AUTOSAR XML (schema 4-2-2)
package /AUTOLIV/SoftwareComponents/SBC
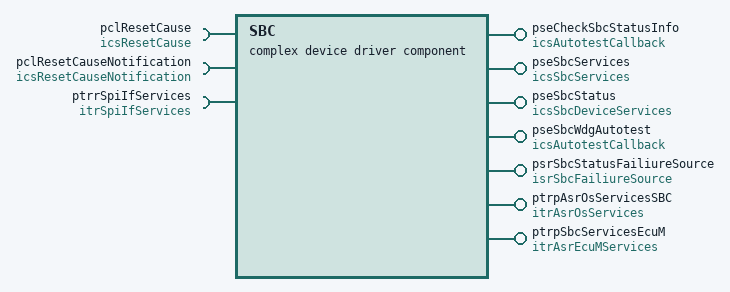
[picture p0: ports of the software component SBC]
  complex device driver sw component type SBC: category=MCAL_Communication_Abstraction
    require port pclResetCause: required-com-specs=[DetermineResetCause, GetResetCause], required-interface=icsResetCause  # Architecture Element ID - ARCH_SW_SBC_pclResetCause_SBC_Autotest_WdgTest # Description - The runnable shall provide the SBC reset reason to the application. # Data Flow ## Inputs ## Outputs # Linked Runnable - SBC_Autotest_WdgTest #Traceability
    require port pclResetCauseNotification: client-com-spec=NotifyResetCause, required-interface=icsResetCauseNotification  # Architecture Element ID - ARCH_SW_SBC_pclResetCauseNotification_SBC_Init # Description - The runnable shall store the SBC reset reason in the no init ram area. # Data Flow ## Inputs ## Outputs # Linked Runnable - SBC_Init #Traceability
    7 x provide port:
      pseCheckSbcStatusInfo: server-com-spec{operation=AutotestCallback, queue-length=1}, provided-interface=icsAutotestCallback  # Architecture Element ID - ARCH_SW_SBC_pseCheckSbcStatusInfo # Description - The autotest shall check the Status information section of a Spi response from the SBC chip - If one or more bits of status information are qualified within 100ms then the result of autotest shall be NOK # Data Flow ## Inputs ## Outputs - {Autotest Result} - Can be one of the following values: OK, NOK, NOT DECIDED # Linked Runnable - SBC_Autotest_CheckStatusInformation #Traceability DOM_eCS_TF_H_309 DOM_eCS_TF_H_310 DOM_eCS_TF_H_311 FUSA_DS_TLE9461_3ES_1034 FUSA_DS_TLE9461_3ES_1042 FUSA_DS_TLE9461_3ES_1046 FUSA_DS_TLE9461_3ES_1047 FUSA_DS_TLE9461_3ES_1058 FUSA_DS_TLE9461_3ES_1127
      pseSbcServices: provided-interface=icsSbcServices  # Architecture Element ID - ARCH_SW_SBC_pseSbcServicesLpm_SBC_sleepTriggerWatchdog # Description - The SBC_sleepTriggerWatchdog runnable shall be called by LPM module to trigger the watchdog during init and mainloop phase (LPM_sleepInit and LPM_sleepMainLoop) # Data Flow ## Inputs ## Outputs # Linked Runnable - SBC_sleepTriggerWatchdog #Traceability FUSA_DS_TLE9461_3ES_731 FUSA_DS_TLE9461_3ES_1000 FUSA_DS_TLE9461_3ES_1127 ------------------------------------------------------------------------------------ Architecture Element ID - ARCH_SW_SBC_pseSbcServicesLpm_SBC_SetToNormal # Description - The SBC_SetToNormal runnable shall be called to put the SBC in normal mode state (LPM_sleepRestore) # Data Flow ## Inputs ## Outputs # Linked Runnable - SBC_SetToNormal #Traceability FUSA_DS_TLE9461_3ES_1127 ------------------------------------------------------------------------------------ Architecture Element ID - ARCH_SW_SBC_pseSbcServicesLpm_SBC_SetToLowPower # Description - The SBC_SetToLowPower runnable shall be called to put the SBC in low power mode (LPM_sleepInit) # Data Flow ## Inputs ## Outputs # Linked Runnable - SBC_SetToLowPower #Traceability FUSA_DS_TLE9461_3ES_227 FUSA_DS_TLE9461_3ES_1127 ------------------------------------------------------------------------------------
        provided-com-specs:
          operation=SBC_sleepTriggerWatchdog, queue-length=1
          operation=SBC_SetToLowPower, queue-length=1
          operation=SBC_SetToNormal, queue-length=1
      pseSbcStatus: provided-interface=icsSbcDeviceServices  # Architecture Element ID - ARCH_SW_SBC_pseSbcStatus_SBC_GetSBCStatusInformation # Description - The runnable shall read the SBC status registers and report them via the {SBC Status Information} output parameter - The following flags should be reported: - Under voltage - CAN wake-up - Watchdog failure # Data Flow ## Inputs ## Outputs - {SBC Status Information} # Linked Runnable - SBC_GetSBCStatusInformation #Traceability FUSA_DS_TLE9461_3ES_1127 ------------------------------------------------------------------------------------ Architecture Element ID - ARCH_SW_SBC_pseSbcStatus_SBC_Shutdown # Description - The SBC_Shutdown runnable shall be called by the Autosar EcuM in deinitialization phase (EcuM_AL_SwitchOff) # Data Flow ## Inputs ## Outputs # Linked Runnable - SBC_Shutdown #Traceability FUSA_DS_TLE9461_3ES_1127 ------------------------------------------------------------------------------------ Architecture Element ID - ARCH_SW_SBC_pseSbcStatus_SBC_Reset # Description - The SBC_Reset runnable shall be called in order to make a reset (EcuM_AL_Reset and MIC_MachineExceptionInterrupt) # Data Flow ## Inputs ## Outputs # Linked Runnable - SBC_Reset #Traceability FUSA_DS_TLE9461_3ES_941 FUSA_DS_TLE9461_3ES_1127 ------------------------------------------------------------------------------------
        provided-com-specs:
          operation=SBC_Reset, queue-length=1
          operation=SBC_Shutdown, queue-length=1
          operation=GetSbcStatus, queue-length=1
      pseSbcWdgAutotest: server-com-spec{operation=AutotestCallback, queue-length=1}, provided-interface=icsAutotestCallback  # Architecture Element ID - ARCH_SW_SBC_pseSbcWdgAutotest # Description - The autotest shall check the Wdg from the SBC chip - The watchdog is enabled and never triggered, a reset is expected # Data Flow ## Inputs ## Outputs - {Autotest Result} - Can be one of the following values: OK, NOK # Linked Runnable - SBC_Autotest_WdgTest #Traceability FUSA_SM_S32K1XXSM_539 FUSA_SM_S32K1XXSM_541 FUSA_SM_S32K1XXSM_263 FUSA_SM_S32K1XXSM_291 DOM_eCS_TF_H_292 DOM_eCS_TF_H_293 FUSA_DS_TLE9461_3ES_1127
      psrSbcStatusFailiureSource: nonqueued-sender-com-spec{data-element=u32SbcReg1Status, uses-end-to-end-protection=0, init-value=0}, provided-interface=isrSbcFailiureSource  # Architecture Element ID - ARCH_SW_SBC_psrSbcStatusFailiureSource_SBC_Init # Description - The runnable shall read the content of the SBC status registers that were previously read from the SPI bus - The runnable shall write the content of the SBC Status Registers on the {SBC Status Register} output parameter. # Data Flow ## Inputs ## Outputs - {SBC Status Register} # Linked Runnable - SBC_Init #Traceability ------------------------------------------------------------------- Architecture Element ID - ARCH_SW_SBC_psrSbcStatusFailiureSource_SBC_runMainFunction # Description - The runnable shall read the content of the SBC status registers that were previously read from the SPI bus - The runnable shall write the content of the SBC Status Registers on the {SBC Status Register} output parameter. # Data Flow ## Inputs - None ## Outputs - {SBC Status Register} # Linked Runnable - SBC_runMainFunction #Traceability
      ptrpAsrOsServicesSBC: provided-interface=itrAsrOsServices  # Architecture Element ID - ARCH_SW_SBC_ptrpAsrOsServices # Description - The runnable shall be called periodically at 10ms in order to trigger the watchdog - The watchdog should be trigger in windowed mode each 40ms # Data Flow ## Inputs ## Outputs # Linked Runnable - SBC_runMainFunction #Traceability FUSA_DS_TLE9461_3ES_970 FUSA_DS_TLE9461_3ES_992 FUSA_DS_TLE9461_3ES_993 FUSA_DS_TLE9461_3ES_994 FUSA_DS_TLE9461_3ES_1014 FUSA_DS_TLE9461_3ES_1019 FUSA_DS_TLE9461_3ES_1025 FUSA_DS_TLE9461_3ES_1026 FUSA_DS_TLE9461_3ES_1061 FUSA_DS_TLE9461_3ES_1064 FUSA_DS_TLE9461_3ES_1065 FUSA_DS_TLE9461_3ES_1086 FUSA_DS_TLE9461_3ES_1127 FUSA_DS_TLE9461_3ES_1128 FUSA_DS_TLE9461_3ES_1132 FUSA_DS_TLE9461_3ES_1139 FUSA_DS_TLE9461_3ES_1151 FUSA_DS_TLE9461_3ES_1181 FUSA_DS_TLE9461_3ES_1182 FUSA_DS_TLE9461_3ES_1183 FUSA_DS_TLE9461_3ES_1254 FUSA_DS_TLE9461_3ES_1255 FUSA_DS_TLE9461_3ES_1256
      ptrpSbcServicesEcuM: provided-interface=itrAsrEcuMServices  # Architecture Element ID - ARCH_SW_SBC_ptrpSbcServicesEcuM_SBC_Init # Description - The SBC_Init runnable shall be called by the Autosar EcuM in initialization phase(EcuM_DefaultInitListOne) # Data Flow ## Inputs ## Outputs # Linked Runnable - SBC_Init #Traceability DOM_eCS_TF_H_291 FUSA_DS_TLE9461_3ES_155 FUSA_DS_TLE9461_3ES_174 FUSA_DS_TLE9461_3ES_196 FUSA_DS_TLE9461_3ES_202 FUSA_DS_TLE9461_3ES_213 FUSA_DS_TLE9461_3ES_217 FUSA_DS_TLE9461_3ES_262 FUSA_DS_TLE9461_3ES_263 FUSA_DS_TLE9461_3ES_265 FUSA_DS_TLE9461_3ES_282 FUSA_DS_TLE9461_3ES_285 FUSA_DS_TLE9461_3ES_950 FUSA_DS_TLE9461_3ES_952 FUSA_DS_TLE9461_3ES_955 FUSA_DS_TLE9461_3ES_956 FUSA_DS_TLE9461_3ES_957 FUSA_DS_TLE9461_3ES_964 FUSA_DS_TLE9461_3ES_1005 FUSA_DS_TLE9461_3ES_1026 FUSA_DS_TLE9461_3ES_1127 FUSA_DS_TLE9461_3ES_1127 FUSA_DS_TLE9461_3ES_1128 FUSA_DS_TLE9461_3ES_1132 FUSA_DS_TLE9461_3ES_1133 FUSA_DS_TLE9461_3ES_1139 FUSA_DS_TLE9461_3ES_1151 FUSA_DS_TLE9461_3ES_1181 FUSA_DS_TLE9461_3ES_1182 FUSA_DS_TLE9461_3ES_1183 FUSA_DS_TLE9461_3ES_1254 FUSA_DS_TLE9461_3ES_1255 FUSA_DS_TLE9461_3ES_1256
    require port ptrrSpiIfServices: required-interface=itrSpiIfServices  # # Architecture Element ID - ARCH_SW_SBC_ptrrSpiIfServices_SpiIf_spiSyncTransmitSequence_SBC_Init # Description - The runnable shall trigger the watchdog first time with the SpiIf_spiSyncTransmitSequence interface - The runnable shall initialize the TLE9461 SBC with the help of the SpiIf_spiSyncTransmitSequence interface # Data Flow ## Inputs ## Outputs # Linked Runnable - SBC_Init #Traceability ------------------------------------------------------------------------------------ # Architecture Element ID - ARCH_SW_SBC_ptrrSpiIfServices_SpiIf_spiReadIBFromChannel_SBC_Init # Description - The runnable shall read the SBC status registers with the SpiIf_spiReadIBFromChannel interface # Data Flow ## Inputs ## Outputs # Linked Runnable - SBC_Init #Traceability ------------------------------------------------------------------------------------ # Architecture Element ID - ARCH_SW_SBC_ptrrSpiIfServices_SpiIf_writeSpiData_SBC_Init # Description - The runnable shall clear errors in status register of SBC with the SpiIf_writeSpiData interface # Data Flow ## Inputs ## Outputs # Linked Runnable - SBC_Init #Traceability ------------------------------------------------------------------------------------ # Architecture Element ID - ARCH_SW_SBC_ptrrSpiIfServices_SpiIf_spiSyncTransmitSequence_SBC_runMainFunction # Description - The runnable shall trigger the watchdog periodically with the SpiIf_spiSyncTransmitSequence interface # Data Flow ## Inputs ## Outputs # Linked Runnable - SBC_runMainFunction #Traceability ------------------------------------------------------------------------------------ # Architecture Element ID - ARCH_SW_SBC_ptrrSpiIfServices_SpiIf_spiReadIBFromChannel_SBC_runMainFunction # Description - The runnable shall read the SBC status registers with the SpiIf_writeSpiData and SpiIf_spiReadIBFromChannel interfaces # Data Flow ## Inputs ## Outputs # Linked Runnable - SBC_runMainFunction #Traceability ------------------------------------------------------------------------------------ # Architecture Element ID - ARCH_SW_SBC_ptrrSpiIfServices_SpiIf_writeSpiData_SBC_runMainFunction # Description - The runnable shall clear the SBC status registers with the SpiIf_writeSpiData interface # Data Flow ## Inputs ## Outputs # Linked Runnable - SBC_runMainFunction #Traceability ------------------------------------------------------------------------------------ Architecture Element ID - ARCH_SW_SBC_ptrrSpiIfServices_SpiIf_spiSyncTransmitSequence_SBC_Shutdown # Description - The runnable shall set the SBC registers in order to prepare the next wake-up using the SpiIf_spiSyncTransmitSequence interface # Data Flow ## Inputs ## Outputs # Linked Runnable - SBC_Shutdown #Traceability ------------------------------------------------------------------------------------ Architecture Element ID - ARCH_SW_SBC_ptrrSpiIfServices_SpiIf_spiSyncTransmitSequence_SBC_sleepTriggerWatchdog # Description - The runnable shall trigger the watchdog periodically using the SpiIf_spiSyncTransmitSequence interface, when the ECU is in sleep mode # Data Flow ## Inputs ## Outputs # Linked Runnable - SBC_sleepTriggerWatchdog #Traceability ------------------------------------------------------------------------------------ Architecture Element ID - ARCH_SW_SBC_ptrrSpiIfServices_SpiIf_spiSyncTransmitSequence_SBC_SetToNormal # Description - The runnable shall set the SBC registers in order to set the SBC in normal mode, using the SpiIf_spiSyncTransmitSequence interface # Data Flow ## Inputs ## Outputs # Linked Runnable - SBC_SetToNormal #Traceability ------------------------------------------------------------------------------------ Architecture Element ID - ARCH_SW_SBC_ptrrSpiIfServices_SpiIf_spiSyncTransmitSequence_SBC_SetToLowPower # Description - The runnable shall set the SBC registers in order to set the SBC in low power mode, using the SpiIf_spiSyncTransmitSequence interface # Data Flow ## Inputs ## Outputs # Linked Runnable - SBC_SetToLowPower #Traceability ------------------------------------------------------------------------------------ Architecture Element ID - ARCH_SW_SBC_ptrrSpiIfServices_SpiIf_spiSyncTransmitSequence_SBC_Reset # Description - The runnable shall set the SBC registers in order to reset the ECU, using the SpiIf_spiSyncTransmitSequence interface # Data Flow ## Inputs ## Outputs # Linked Runnable - SBC_Reset #Traceability
  swc implementation SBC_imp: category=MCAL_Communication_Abstraction, programming-language=C, sw-version=1.0.0, vendor-id=0, behavior=SBC_IB
    code-descriptors:
      code SBC_Impl_Code: artifact-descriptors=autosar-engineering-object={short-label=SBC_Impl_Code_CodeDesc, category=SWSRC}
    resource consumption SBC_ImplResCons
      33 x memory section:
        CODE: size=0, sw-addrmethod=CODE
        CODE_ASIL_A: size=0, sw-addrmethod=CODE_ASIL_A
        CONST_16: alignment=16, size=16, sw-addrmethod=CONST
        CONST_16_ASIL_A: alignment=16, size=16, sw-addrmethod=CONST_ASIL_A
        CONST_32: alignment=32, size=32, sw-addrmethod=CONST
        CONST_32_ASIL_A: alignment=32, size=32, sw-addrmethod=CONST_ASIL_A
        CONST_8: alignment=8, size=8, sw-addrmethod=CONST
        CONST_8_ASIL_A: alignment=8, size=8, sw-addrmethod=CONST_ASIL_A
        CONST_BOOL: alignment=8, size=1, sw-addrmethod=CONST
        CONST_BOOL_ASIL_A: alignment=8, size=1, sw-addrmethod=CONST_ASIL_A
        CONST_UNSPECIFIED: alignment=UNSPECIFIED, size=0, sw-addrmethod=CONST
        CONST_UNSPECIFIED_ASIL_A: alignment=UNSPECIFIED, size=0, sw-addrmethod=CONST_ASIL_A
        VAR_INIT_16: alignment=16, size=16, sw-addrmethod=VAR_INIT
        VAR_INIT_16_ASIL_A: alignment=16, size=16, sw-addrmethod=VAR_INIT_ASIL_A
        VAR_INIT_32: alignment=32, size=32, sw-addrmethod=VAR_INIT
        VAR_INIT_32_ASIL_A: alignment=32, size=32, sw-addrmethod=VAR_INIT_ASIL_A
        VAR_INIT_8: alignment=8, size=8, sw-addrmethod=VAR_INIT
        VAR_INIT_8_ASIL_A: alignment=8, size=8, sw-addrmethod=VAR_INIT_ASIL_A
        VAR_INIT_BOOL: alignment=8, size=1, sw-addrmethod=VAR_INIT
        VAR_INIT_BOOL_ASIL_A: alignment=8, size=1, sw-addrmethod=VAR_INIT_ASIL_A
        VAR_INIT_UNSPECIFIED: alignment=UNSPECIFIED, size=0, sw-addrmethod=VAR_INIT
        VAR_INIT_UNSPECIFIED_ASIL_A: alignment=UNSPECIFIED, size=0, sw-addrmethod=VAR_INIT_ASIL_A
        VAR_NO_INIT_16: alignment=16, size=16, sw-addrmethod=VAR_NOINIT
        VAR_NO_INIT_16_ASIL_A: alignment=16, size=16, sw-addrmethod=VAR_NOINIT_ASIL_A
        VAR_NO_INIT_32: alignment=32, size=32, sw-addrmethod=VAR_NOINIT
        VAR_NO_INIT_32_ASIL_A: alignment=32, size=32, sw-addrmethod=VAR_NOINIT_ASIL_A
        VAR_NO_INIT_8: alignment=8, size=8, sw-addrmethod=VAR_NOINIT
        VAR_NO_INIT_8_ASIL_A: alignment=8, size=8, sw-addrmethod=VAR_NOINIT_ASIL_A
        VAR_NO_INIT_BOOL: alignment=8, size=1, sw-addrmethod=VAR_NOINIT
        VAR_NO_INIT_BOOL_ASIL_A: alignment=8, size=1, sw-addrmethod=VAR_NOINIT_ASIL_A
        VAR_NO_INIT_UNSPECIFIED: alignment=UNSPECIFIED, size=0
        VAR_NO_INIT_UNSPECIFIED_ASIL_A: alignment=UNSPECIFIED, size=0
        VAR_POWER_ON_CLEARED: alignment=UNSPECIFIED, size=0, sw-addrmethod=VAR_POWER_ON_CLEARED
